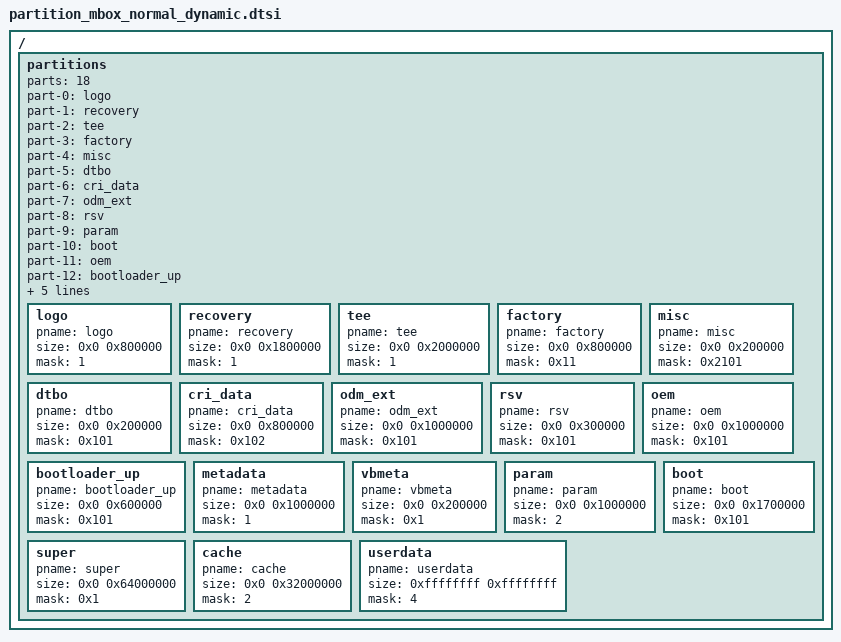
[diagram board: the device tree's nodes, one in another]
// SPDX-License-Identifier: (GPL-2.0+ OR MIT)
/*
 * Copyright (c) 2019 Amlogic, Inc. All rights reserved.
 */

#include "firmware_avb_Q.dtsi"

/ {
    partitions: partitions{
		parts = <18>;
		part-0 = <&logo>;
		part-1 = <&recovery>;
		part-2 = <&tee>;
		part-3 = <&factory>;
		part-4 = <&misc>;
		part-5 = <&dtbo>;
		part-6 = <&cri_data>;
		part-7 = <&odm_ext>;
		part-8 = <&rsv>;
		part-9 = <&param>;
		part-10 = <&boot>;
		part-11 = <&oem>;
		part-12 = <&bootloader_up>;
		part-13 = <&metadata>;
		part-14 = <&vbmeta>;
		part-15 = <&super>;
		part-16 = <&cache>;
		part-17 = <&userdata>;

		logo:logo{
			pname = "logo";
			size = <0x0 0x800000>;
			mask = <1>;
		};
		recovery:recovery{
			pname = "recovery";
			size = <0x0 0x1800000>;
			mask = <1>;
		};
		tee:tee{
			pname = "tee";
			size = <0x0 0x2000000>;
			mask = <1>;
		};
		factory:factory{
			pname = "factory";
			size = <0x0 0x800000>;
			mask = <0x11>;
		};
		misc:misc{
			pname = "misc";
			size = <0x0 0x200000>;
			mask = <0x2101>;
		};
		dtbo:dtbo{
			pname = "dtbo";
			size = <0x0 0x200000>;
			mask = <0x101>;
		};
		cri_data:cri_data
		{
			pname = "cri_data";
			size = <0x0 0x800000>;
			mask = <0x102>;
		};
		odm_ext:odm_ext{
			pname = "odm_ext";
			size = <0x0 0x1000000>;
			mask = <0x101>;
		};
		rsv:rsv
		{
			pname = "rsv";
			size = <0x0 0x300000>;
			mask = <0x101>;
		};
		oem:oem{
			pname = "oem";
			size = <0x0 0x1000000>;
			mask = <0x101>;
		};
		bootloader_up:bootloader_up
		{
			pname = "bootloader_up";
			size = <0x0 0x600000>;
			mask = <0x101>;
		};
		metadata:metadata{
			pname = "metadata";
			size = <0x0 0x1000000>;
			mask = <1>;
		};
		vbmeta:vbmeta{
			pname = "vbmeta";
			size = <0x0 0x200000>;
			mask = <0x1>;
		};
		param:param{
			pname = "param";
			size = <0x0 0x1000000>;
			mask = <2>;
		};
		boot:boot
		{
			pname = "boot";
			size = <0x0 0x1700000>;
			mask = <0x101>;
		};
		super:super
		{
			pname = "super";
			size = <0x0 0x64000000>;
			mask = <0x1>;
		};
		cache:cache
		{
			pname = "cache";
			size = <0x0 0x32000000>;
			mask = <2>;
		};
		userdata:userdata
		{
			pname = "userdata";
			size = <0xffffffff 0xffffffff>;
			mask = <4>;
		};
	};
};/* end of / */
